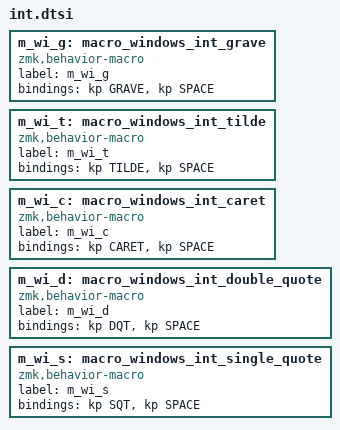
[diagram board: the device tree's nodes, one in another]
// action:     `
m_wi_g: macro_windows_int_grave {
    compatible = "zmk,behavior-macro";
    label = "m_wi_g";
    #binding-cells = <0>;
    bindings =
        <&kp GRAVE &kp SPACE>;
};

// action:     ~
m_wi_t: macro_windows_int_tilde {
    compatible = "zmk,behavior-macro";
    label = "m_wi_t";
    #binding-cells = <0>;
    bindings =
        <&kp TILDE &kp SPACE>;
};

// action:     ^
m_wi_c: macro_windows_int_caret {
    compatible = "zmk,behavior-macro";
    label = "m_wi_c";
    #binding-cells = <0>;
    bindings =
        <&kp CARET &kp SPACE>;
};

// action:     "
m_wi_d: macro_windows_int_double_quote {
    compatible = "zmk,behavior-macro";
    label = "m_wi_d";
    #binding-cells = <0>;
    bindings =
        <&kp DQT &kp SPACE>;
};

// action:     '
m_wi_s: macro_windows_int_single_quote {
    compatible = "zmk,behavior-macro";
    label = "m_wi_s";
    #binding-cells = <0>;
    bindings =
        <&kp SQT &kp SPACE>;
};
